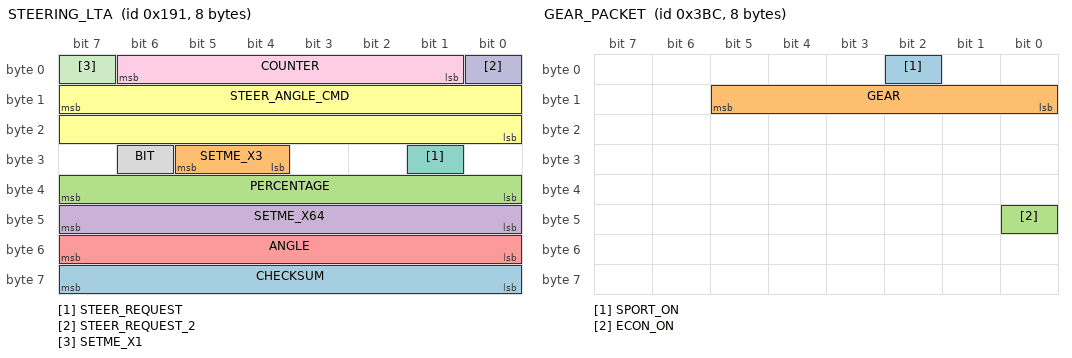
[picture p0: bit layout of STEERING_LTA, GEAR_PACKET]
BO_ 401 STEERING_LTA: 8 XXX
 SG_ CHECKSUM : 63|8@0+ (1,0) [0|255] "" XXX
 SG_ SETME_X3 : 29|2@0+ (1,0) [0|3] "" XXX
 SG_ PERCENTAGE : 39|8@0+ (1,0) [0|255] "" XXX
 SG_ SETME_X64 : 47|8@0+ (1,0) [0|255] "" XXX
 SG_ ANGLE : 55|8@0- (0.5,0) [0|255] "" XXX
 SG_ STEER_ANGLE_CMD : 15|16@0- (0.0573,0) [-540|540] "" XXX
 SG_ STEER_REQUEST : 25|1@0+ (1,0) [0|1] "" XXX
 SG_ BIT : 30|1@0+ (1,0) [0|1] "" XXX
 SG_ COUNTER : 6|6@0+ (1,0) [0|255] "" XXX
 SG_ STEER_REQUEST_2 : 0|1@0+ (1,0) [0|1] "" XXX
 SG_ SETME_X1 : 7|1@0+ (1,0) [0|1] "" XXX

BO_ 956 GEAR_PACKET: 8 XXX
 SG_ SPORT_ON : 2|1@0+ (1,0) [0|1] "" XXX
 SG_ GEAR : 13|6@0+ (1,0) [0|63] "" XXX
 SG_ ECON_ON : 40|1@0+ (1,0) [0|1] "" XXX

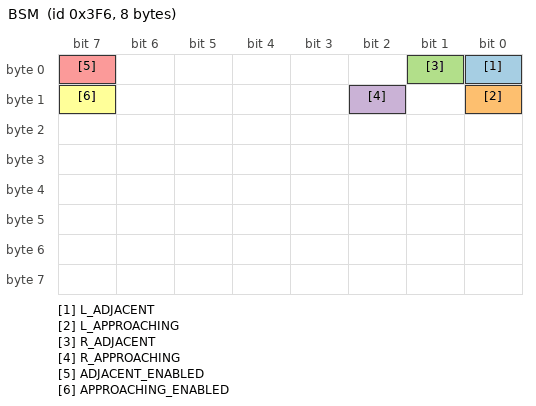
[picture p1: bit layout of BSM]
BO_ 1014 BSM: 8 XXX
 SG_ L_ADJACENT : 0|1@0+ (1,0) [0|1] "" XXX
 SG_ L_APPROACHING : 8|1@0+ (1,0) [0|1] "" XXX
 SG_ R_ADJACENT : 1|1@0+ (1,0) [0|1] "" XXX
 SG_ R_APPROACHING : 10|1@0+ (1,0) [0|1] "" XXX
 SG_ ADJACENT_ENABLED : 7|1@0+ (1,0) [0|1] "" XXX
 SG_ APPROACHING_ENABLED : 15|1@0+ (1,0) [0|1] "" XXX

VAL_ 956 GEAR 0 "D" 1 "S" 8 "N" 16 "R" 32 "P";
CM_ SG_ 1014 L_ADJACENT "vehicle adjacent left side of car. enabled above 10mph, regardless of ADJACENT_ENABLED or APPROACHING_ENABLED";
CM_ SG_ 1014 L_APPROACHING "vehicle approaching from left side of car. enabled above 10mph, regardless of ADJACENT_ENABLED or APPROACHING_ENABLED";
CM_ SG_ 1014 R_ADJACENT "vehicle adjacent right side of car. enabled above 10mph, regardless of ADJACENT_ENABLED or APPROACHING_ENABLED";
CM_ SG_ 1014 R_APPROACHING "vehicle approaching from right side of car. enabled above 10mph, regardless of ADJACENT_ENABLED or APPROACHING_ENABLED";
CM_ SG_ 1014 ADJACENT_ENABLED "when BSM is enabled in settings, this is on along with APPROACHING_ENABLED. this controls bsm alert visibility";
CM_ SG_ 1014 APPROACHING_ENABLED "when BSM is enabled in settings, this is on along with ADJACENT_ENABLED. this controls bsm alert visibility";
